VERSION "HIPBNYYYYYYYYYYYYYYYYYYYYYYYYYYYYYYYYYYYYY/4/%%%/4/'%**4YYY///"

NS_ :

BS_:

BU_: DBG VCU BMS MCM DCU DAQ S2C

BO_ 2147483904 VCU_RR_Motor: 4 VCU
 SG_ VCU_RR_CurrentCommand : 7|32@0- (0.001,0) [-200|200] "A" MCM

BO_ 2147483905 VCU_RL_Motor: 4 VCU
 SG_ VCU_RL_CurrentCommand : 7|32@0- (0.001,0) [-200|200] "A" MCM

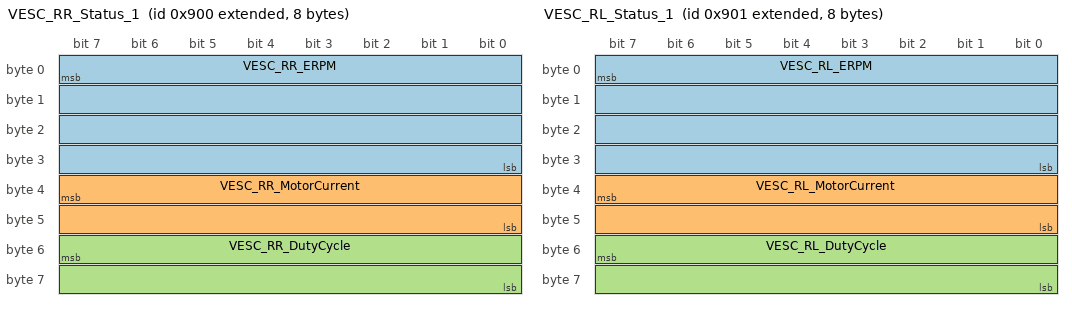
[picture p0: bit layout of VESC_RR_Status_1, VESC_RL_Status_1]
BO_ 2147485952 VESC_RR_Status_1: 8 MCM
 SG_ VESC_RR_ERPM : 7|32@0- (1,0) [-2147483648|2147483647] "ERPM" VCU
 SG_ VESC_RR_MotorCurrent : 39|16@0- (0.1,0) [-3276.8|3276.7] "A" VCU
 SG_ VESC_RR_DutyCycle : 55|16@0- (0.001,0) [-1|1] "" VCU

BO_ 2147485953 VESC_RL_Status_1: 8 MCM
 SG_ VESC_RL_ERPM : 7|32@0- (1,0) [-2147483648|2147483647] "ERPM" VCU
 SG_ VESC_RL_MotorCurrent : 39|16@0- (0.1,0) [-3276.8|3276.7] "A" VCU
 SG_ VESC_RL_DutyCycle : 55|16@0- (0.001,0) [-1|1] "" VCU

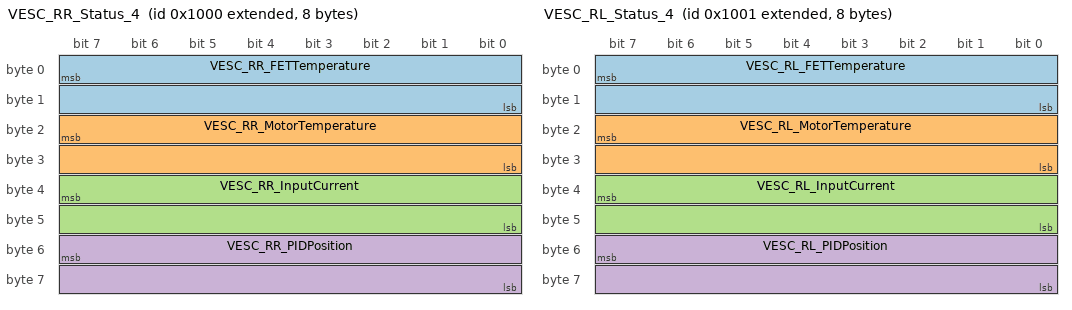
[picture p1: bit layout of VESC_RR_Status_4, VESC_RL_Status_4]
BO_ 2147487744 VESC_RR_Status_4: 8 MCM
 SG_ VESC_RR_FETTemperature : 7|16@0- (0.1,0) [-3276.8|3276.7] "C" VCU
 SG_ VESC_RR_MotorTemperature : 23|16@0- (0.1,0) [-3276.8|3276.7] "C" VCU
 SG_ VESC_RR_InputCurrent : 39|16@0- (0.1,0) [-3276.8|3276.7] "A" VCU
 SG_ VESC_RR_PIDPosition : 55|16@0- (0.02,0) [-655.36|655.34] "deg" VCU

BO_ 2147487745 VESC_RL_Status_4: 8 MCM
 SG_ VESC_RL_FETTemperature : 7|16@0- (0.1,0) [-3276.8|3276.7] "C" VCU
 SG_ VESC_RL_MotorTemperature : 23|16@0- (0.1,0) [-3276.8|3276.7] "C" VCU
 SG_ VESC_RL_InputCurrent : 39|16@0- (0.1,0) [-3276.8|3276.7] "A" VCU
 SG_ VESC_RL_PIDPosition : 55|16@0- (0.02,0) [-655.36|655.34] "deg" VCU

BO_ 2147490560 VESC_RR_Status_5: 8 MCM
 SG_ VESC_RR_Tachometer : 7|32@0- (1,0) [-2147483648|2147483647] "counts" VCU
 SG_ VESC_RR_InputVoltage : 39|16@0+ (0.1,0) [0|6553.5] "V" VCU

BO_ 2147490561 VESC_RL_Status_5: 8 MCM
 SG_ VESC_RL_Tachometer : 7|32@0- (1,0) [-2147483648|2147483647] "counts" VCU
 SG_ VESC_RL_InputVoltage : 39|16@0+ (0.1,0) [0|6553.5] "V" VCU

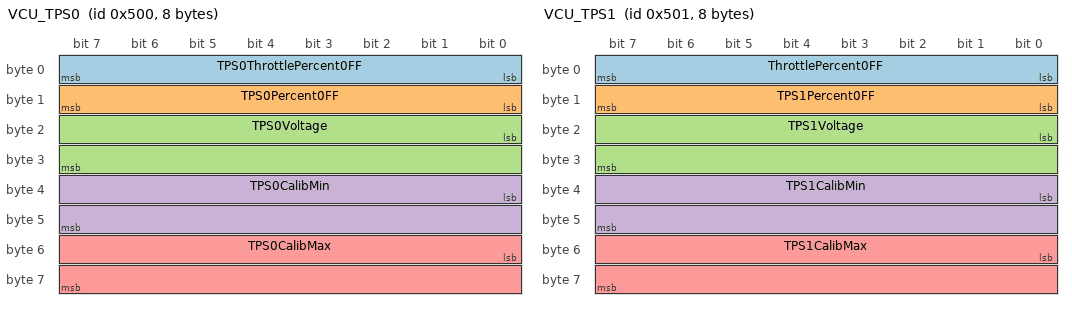
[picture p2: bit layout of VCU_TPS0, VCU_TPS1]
BO_ 1280 VCU_TPS0: 8 VCU
 SG_ TPS0ThrottlePercent0FF : 0|8@1+ (0.392156862746,0) [0|100.00000000023] "%" VCU
 SG_ TPS0Percent0FF : 8|8@1+ (0.392156862746,0) [0|100.00000000023] "%" VCU
 SG_ TPS0Voltage : 16|16@1+ (0.001,0) [0|65.535] "V" VCU
 SG_ TPS0CalibMin : 32|16@1+ (0.001,0) [0|65.535] "V" VCU
 SG_ TPS0CalibMax : 48|16@1+ (0.001,0) [0|65.535] "V" VCU

BO_ 1281 VCU_TPS1: 8 VCU
 SG_ ThrottlePercent0FF : 0|8@1+ (0.392156862746,0) [0|100.00000000023] "%" VCU
 SG_ TPS1Percent0FF : 8|8@1+ (0.392156862746,0) [0|100.00000000023] "%" VCU
 SG_ TPS1Voltage : 16|16@1+ (0.001,0) [0|65.535] "V" VCU
 SG_ TPS1CalibMin : 32|16@1+ (0.001,0) [0|65.535] "V" VCU
 SG_ TPS1CalibMax : 48|16@1+ (0.001,0) [0|65.535] "V" VCU

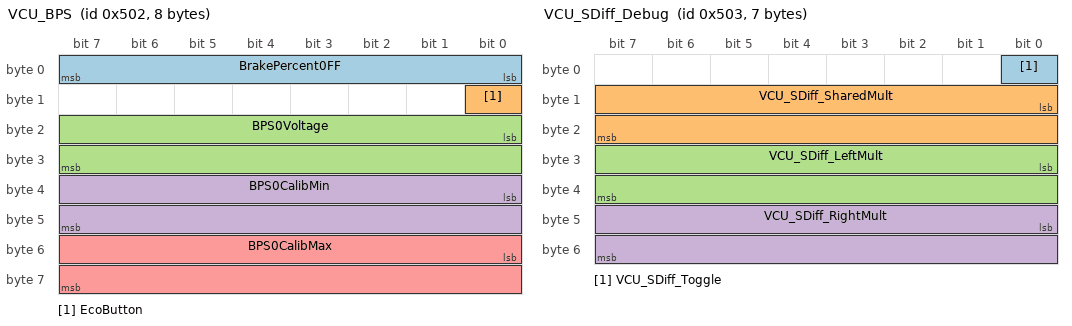
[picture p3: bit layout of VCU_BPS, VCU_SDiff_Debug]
BO_ 1282 VCU_BPS: 8 VCU
SG_ BrakePercent0FF : 0|8@1+ (0.392156862746,0) [0|100.00000000023] "%" VCU
SG_ EcoButton : 8|1@1+ (1,0) [0|1] "" VCU
SG_ BPS0Voltage : 16|16@1+ (0.001,0) [0|65.535] "V" VCU
SG_ BPS0CalibMin : 32|16@1+ (0.001,0) [0|65.535] "V" VCU
SG_ BPS0CalibMax : 48|16@1+ (0.001,0) [0|65.535] "V" VCU

BO_ 1283 VCU_SDiff_Debug: 7 VCU
 SG_ VCU_SDiff_Toggle : 0|1@1+ (1,0) [0|1] "" VCU
 SG_ VCU_SDiff_SharedMult : 8|16@1+ (0.001,0) [0|1] "" VCU
 SG_ VCU_SDiff_LeftMult : 24|16@1+ (0.001,0) [0|1] "" VCU
 SG_ VCU_SDiff_RightMult : 40|16@1+ (0.001,0) [0|1] "" VCU

BO_ 1284 VCU_SAS: 8 VCU
 SG_ SAS_Voltage : 0|16@1+ (0.001,0) [0|5] "V" VCU
 SG_ SAS_SteeringAngle : 16|16@1- (1,0) [-90|90] "deg" VCU

BO_ 1285 VCU_Safety_Checker: 8 VCU
 SG_ VCU_FAULT_TPS_OutOfRange : 0|1@1+ (1,0) [0|1] "" VCU
 SG_ VCU_FAULT_BPS_OutOfRange : 1|1@1+ (1,0) [0|1] "" VCU
 SG_ VCU_FAULT_TPS_PowerFailure : 2|1@1+ (1,0) [0|1] "" VCU
 SG_ VCU_FAULT_BPS_PowerFailure : 3|1@1+ (1,0) [0|1] "" VCU
 SG_ VCU_FAULT_TPS_SignalFailure : 4|1@1+ (1,0) [0|1] "" VCU
 SG_ VCU_FAULT_BPS_SignalFailure : 5|1@1+ (1,0) [0|1] "" VCU
 SG_ VCU_FAULT_TPS_NotCalibrated : 6|1@1+ (1,0) [0|1] "" VCU
 SG_ VCU_FAULT_BPS_NotCalibrated : 7|1@1+ (1,0) [0|1] "" VCU
 SG_ VCU_FAULT_TPS_OutOfSync : 8|1@1+ (1,0) [0|1] "" VCU
 SG_ VCU_FAULT_TPSBPS_Implausible : 10|1@1+ (1,0) [0|1] "" VCU
 SG_ VCU_FAULT_BSPD_SoftFault : 12|1@1+ (1,0) [0|1] "" VCU
 SG_ VCU_FAULT_LVS_BatteryEmpty : 16|1@1+ (1,0) [0|1] "" VCU
 SG_ VCU_FAULT_BMS_OverVoltage : 20|1@1+ (1,0) [0|1] "" VCU
 SG_ VCU_FAULT_BMS_UnderVoltage : 21|1@1+ (1,0) [0|1] "" VCU
 SG_ VCU_FAULT_BMS_OverTemperature : 22|1@1+ (1,0) [0|1] "" VCU
 SG_ VCU_FAULT_BMS_CommunicationLost : 23|1@1+ (1,0) [0|1] "" VCU
 SG_ VCU_FAULT_BMS_CellMismatch : 24|1@1+ (1,0) [0|1] "" VCU
 SG_ VCU_WARNING_LVS_BatteryLow : 32|1@1+ (1,0) [0|1] "" VCU
 SG_ VCU_WARNING_BMS_OverVoltage : 40|1@1+ (1,0) [0|1] "" VCU
 SG_ VCU_WARNING_BMS_UnderVoltage : 41|1@1+ (1,0) [0|1] "" VCU
 SG_ VCU_WARNING_BMS_OverTemperature : 42|1@1+ (1,0) [0|1] "" VCU
 SG_ VCU_WARNING_HVIL_OverrideEn : 38|1@1+ (1,0) [0|1] "" VCU
 SG_ VCU_WARNING_SAFETY_BypassEn : 39|1@1+ (1,0) [0|1] "" VCU
 SG_ VCU_NOTICE_HVIL_TermSenseLost : 48|1@1+ (1,0) [0|1] "" VCU
 SG_ VCU_NOTICE_BMS_Over75kW : 52|1@1+ (1,0) [0|1] "" VCU
 SG_ VCU_NOTICE_MCM_Over75kW : 53|1@1+ (1,0) [0|1] "" VCU

BO_ 1286 Low_Voltage: 8 VCU
 SG_ Voltage : 0|16@1+ (0.001,0) [0|65.535] "V" VCU
 SG_ StateOfCharge : 16|8@1+ (1,0) [0|100] "%" VCU

BO_ 1287 MCM_RTD_HVIL: 8 VCU
 SG_ HVIL_Active : 0|1@1+ (1,0) [0|1] "" VCU

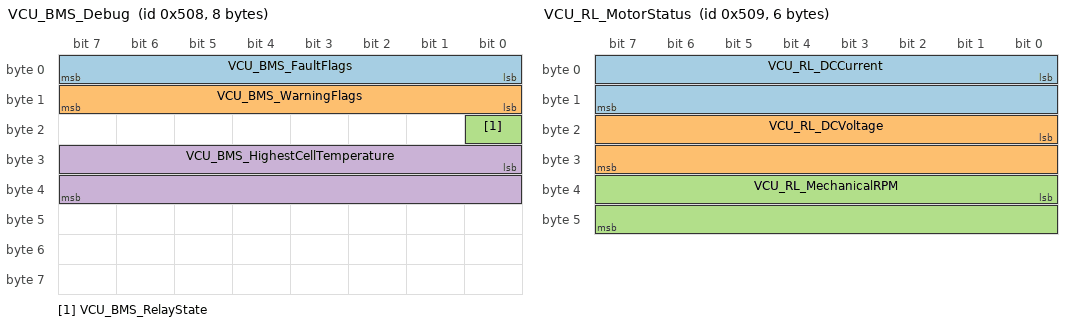
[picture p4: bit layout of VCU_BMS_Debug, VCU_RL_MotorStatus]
BO_ 1288 VCU_BMS_Debug: 8 VCU
 SG_ VCU_BMS_FaultFlags : 0|8@1+ (1,0) [0|255] "" VCU
 SG_ VCU_BMS_WarningFlags : 8|8@1+ (1,0) [0|255] "" VCU
 SG_ VCU_BMS_RelayState : 16|1@1+ (1,0) [0|1] "" VCU
 SG_ VCU_BMS_HighestCellTemperature : 24|16@1- (0.1,0) [-3276.8|3276.7] "C" VCU

BO_ 1289 VCU_RL_MotorStatus: 6 VCU
 SG_ VCU_RL_DCCurrent : 0|16@1- (1,0) [-32768|32767] "A" VCU
 SG_ VCU_RL_DCVoltage : 16|16@1+ (1,0) [0|65535] "V" VCU
 SG_ VCU_RL_MechanicalRPM : 32|16@1- (1,0) [-32768|32767] "RPM" VCU

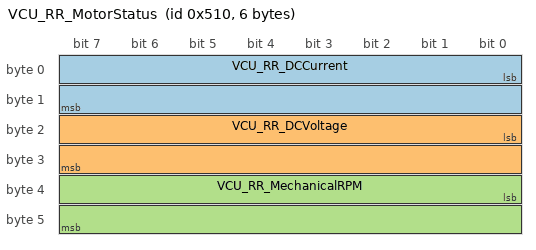
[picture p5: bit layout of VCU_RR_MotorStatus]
BO_ 1296 VCU_RR_MotorStatus: 6 VCU
 SG_ VCU_RR_DCCurrent : 0|16@1- (1,0) [-32768|32767] "A" VCU
 SG_ VCU_RR_DCVoltage : 16|16@1+ (1,0) [0|65535] "V" VCU
 SG_ VCU_RR_MechanicalRPM : 32|16@1- (1,0) [-32768|32767] "RPM" VCU

BO_ 1535 VCU_DebugControl: 1 DBG
 SG_ VCU_SafetyBypassCode : 0|8@1+ (1,0) [0|255] "" VCU

BO_ 1541 BMS_PrechargeCommand: 1 VCU
 SG_ BMS_PrechargeRequest : 0|1@1+ (1,0) [0|1] "" BMS

CM_ BU_ VCU "The vehicle control unit";
CM_ BU_ MCM "The VESC motor controllers";
CM_ BU_ BMS "The battery management system";
CM_ BU_ DCU "The dash control unit";
CM_ BO_ 1280 "VCU throttle position sensor 0 debug frame";
CM_ BO_ 1281 "VCU throttle position sensor 1 debug frame";
CM_ BO_ 1282 "VCU brake pressure sensor debug frame";
CM_ BO_ 1283 "VCU software differential debug frame";
CM_ BO_ 1284 "VCU steering angle sensor debug frame";
CM_ BO_ 1285 "VCU safety flags";
CM_ BO_ 1286 "VCU low-voltage battery debug frame";
CM_ BO_ 1287 "VCU HVIL termination sense debug frame";
CM_ BO_ 1288 "VCU BMS loopback debug frame";
CM_ BO_ 1289 "VCU rear-left motor status debug frame";
CM_ BO_ 1296 "VCU rear-right motor status debug frame";
CM_ BO_ 1535 "VCU safety bypass input";
CM_ BO_ 1541 "VCU precharge request to the BMS";
CM_ BO_ 2147483904 "VESC set-current command for controller 0, rear right";
CM_ BO_ 2147483905 "VESC set-current command for controller 1, rear left";
CM_ BO_ 2147485952 "VESC status packet 1 from controller 0, rear right";
CM_ BO_ 2147485953 "VESC status packet 1 from controller 1, rear left";
CM_ BO_ 2147487744 "VESC status packet 4 from controller 0, rear right";
CM_ BO_ 2147487745 "VESC status packet 4 from controller 1, rear left";
CM_ BO_ 2147490560 "VESC status packet 5 from controller 0, rear right";
CM_ BO_ 2147490561 "VESC status packet 5 from controller 1, rear left";

BA_DEF_ "BusType" STRING ;
BA_DEF_DEF_ "BusType" "CAN";

VAL_ 1283 VCU_SDiff_Toggle 0 "Disabled" 1 "Enabled" ;
VAL_ 1288 VCU_BMS_RelayState 0 "Open" 1 "Closed" ;
VAL_ 1535 VCU_SafetyBypassCode 196 "Enable" ;
VAL_ 1541 BMS_PrechargeRequest 0 "Open" 1 "Close" ;
